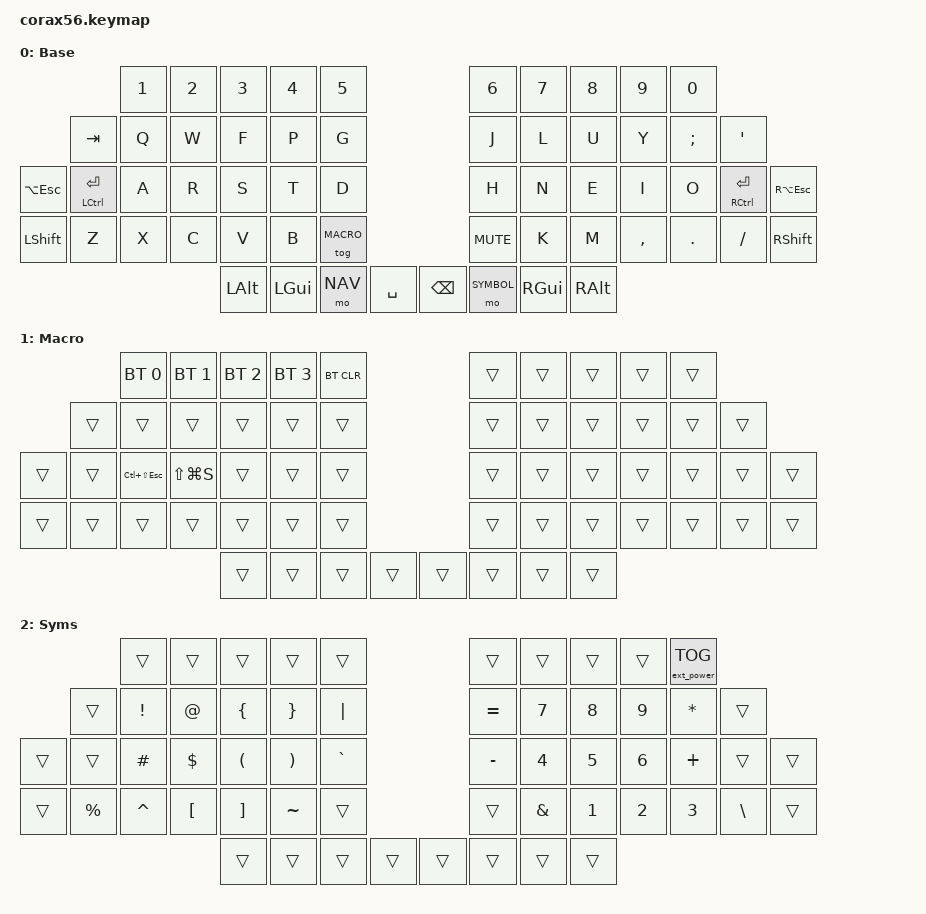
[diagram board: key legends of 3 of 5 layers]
#include <behaviors.dtsi>
#include <dt-bindings/zmk/bt.h>
#include <dt-bindings/zmk/keys.h>
#include <dt-bindings/zmk/outputs.h>


#define ___ &trans
#define BASE 0
#define NAV 1
#define MACRO 2
#define SYMBOL 3
#define NUM 4
#define FUNC 5

// urob includes (https://github.com/urob/zmk-nodefree-config)

#include <behaviors.dtsi>
#include "../zmk-nodefree-config/helper.h"
#include "../zmk-nodefree-config/keypos_def/keypos_58keys.h"

// ZMK includes

#include <dt-bindings/zmk/bt.h>
#include <dt-bindings/zmk/ext_power.h>
#include <dt-bindings/zmk/keys.h>

/ {
    behaviors {
        hrm: hrm {
            label = "hrm";
            compatible = "zmk,behavior-hold-tap";
            #binding-cells = <2>;
            flavor = "balanced";
            tapping-term-ms = <280>;
            quick-tap-ms = <125>;
            global-quick-tap;
            bindings =
                <&kp>,
                <&kp>;
        };
    };

    sensors {
        triggers-per-rotation = <20>;
    };
};

&nice_view_spi {
    cs-gpios = <&pro_micro 4 GPIO_ACTIVE_HIGH>;
};

&left_encoder {
    steps = <80>;
};

&right_encoder {
    steps = <80>;
};

/ {
    keymap {
        compatible = "zmk,keymap";

        colemak_layer {
            label = "Base";
            bindings = <
                            &kp N1       &kp N2       &kp N3        &kp N4         &kp N5                                                &kp N6             &kp N7        &kp N8        &kp N9       &kp N0 
            &kp TAB         &kp Q        &kp W        &kp F         &kp P          &kp G                                                 &kp J              &kp L         &kp U         &kp Y        &kp SEMI        &kp SQT
&kp LA(ESC) &mt LCTL ENTER  &kp A        &kp R        &kp S         &kp T          &kp D                                                 &kp H              &kp N         &kp E         &kp I        &kp O           &mt RCTL ENTER  &kp RA(ESC) 
            &kp LSHFT       &kp Z        &kp X        &kp C         &kp V          &kp B         &tog MACRO             &kp C_MUTE       &kp K              &kp M         &kp COMMA     &kp DOT      &kp FSLH        &kp RSHFT
                                                      &kp LALT      &kp LGUI       &mo NAV       &kp SPACE              &kp BKSP         &mo SYMBOL         &kp RGUI      &kp RALT
            >;
            sensor-bindings = <&inc_dec_kp LC(Y) LC(Z) &inc_dec_kp C_VOL_DN C_VOL_UP>;
        };

macro {
            label = "Macro";
            bindings = <
                     &bt BT_SEL 0        &bt BT_SEL 1   &bt BT_SEL 2  &bt BT_SEL 3  &bt BT_CLR                  &trans  &trans  &trans  &trans  &trans 
        &trans       &trans              &trans         &trans        &trans        &trans                      &trans  &trans  &trans  &trans  &trans  &trans
&trans  &trans       &kp LC(LS(ESCAPE))  &kp LS(LG(S))  &trans        &trans        &trans                      &trans  &trans  &trans  &trans  &trans  &trans   &trans
        &trans       &trans              &trans         &trans        &trans        &trans      &trans  &trans  &trans  &trans  &trans  &trans  &trans  &trans
                                                        &trans        &trans        &trans      &trans  &trans  &trans  &trans  &trans
            >;
        };

        symbol {
            label = "Syms";
            bindings = <
                &trans            &trans         &trans            &trans           &trans                      &trans      &trans      &trans          &trans      &ext_power EP_TOG       
        &trans  &kp EXCL          &kp AT         &kp LBRC          &kp RBRC         &kp PIPE                    &kp EQUAL   &kp N7      &kp N8          &kp N9      &kp ASTRK               &trans
&trans  &trans  &kp HASH          &kp DLLR       &kp LPAR          &kp RPAR         &kp GRAVE                   &kp MINUS   &kp N4      &kp N5          &kp N6      &kp PLUS                &trans   &trans
        &trans  &kp PRCNT         &kp CARET      &kp LBKT          &kp RBKT         &kp TILDE   &trans  &trans  &kp AMPS    &kp N1      &kp N2          &kp N3      &kp BSLH                &trans
                                                 &trans            &trans           &trans      &trans  &trans  &trans  &trans  &trans
            >;
        };

        number {
            label = "Nums";
            bindings = <
                      &kp F1        &kp F2        &kp F3        &kp F4        &kp F5                  &trans        &trans        &trans        &trans        &trans        
        &trans        &kp NUMBER_7  &kp NUMBER_8  &kp NUMBER_9  &kp NUMBER_0  &trans                  &trans        &kp NUMBER_7  &kp NUMBER_8  &kp NUMBER_9  &trans        &trans
&trans  &kp NUMBER_0  &kp NUMBER_4  &kp NUMBER_5  &kp NUMBER_6  &kp NUMBER_0  &trans                  &kp NUMBER_0  &kp NUMBER_4  &kp NUMBER_5  &kp NUMBER_6  &kp NUMBER_0  &trans   &trans
        &kp ENTER     &kp NUMBER_1  &kp NUMBER_2  &kp NUMBER_3  &kp ENTER     &trans  &trans  &trans  &kp ENTER     &kp NUMBER_1  &kp NUMBER_2  &kp NUMBER_3  &kp ENTER     &trans
                                                  &trans        &trans        &trans  &trans  &trans  &trans        &trans        &trans        &trans
            >;
        };

        function {
            label = "Function";
            bindings = <
                &trans      &trans   &trans   &trans    &trans                       &trans  &trans  &trans   &trans   &trans   
        &trans  &trans      &kp HOME &kp UP   &kp END   &kp PG_UP                    &trans  &kp F7  &kp F8   &kp F9   &kp F10  &trans
&trans  &trans  &trans      &kp LEFT &kp DOWN &kp RIGHT &kp PG_DN                    &trans  &kp F4  &kp F5   &kp F6   &kp F11  &trans   &trans
        &trans  &trans      &trans   &trans   &trans    &trans       &trans  &trans  &trans  &kp F1  &kp F2   &kp F3   &kp F12  &trans
                                     &trans   &trans    &trans       &trans  &trans  &trans   &trans
            >;
        };
    };
};
